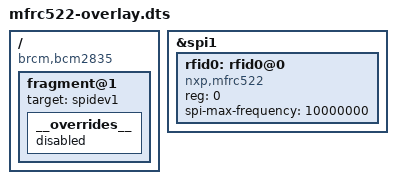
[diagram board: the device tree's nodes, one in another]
/dts-v1/;
/plugin/;


/ {
	compatible = "brcm,bcm2835";

	fragment@0 {
		target = <&spi1>;
		__overlay__ {
			/* needed to avoid dtc warning */
			#address-cells = <1>;
			#size-cells = <0>;
			status = "okay";

             		pinctrl-names = "default";
             		//pinctrl-0 = <&spi0_pins_s0>;

			rfid0: rfid0@0 {
				compatible = "nxp,mfrc522";
				reg = <0>;      /* CE0 */
				spi-max-frequency = <10000000>;
			};
		};
	};

	fragment@1 {
		target = <&spidev1>;
		__overrides__ {
			status = "disabled";
		};
	};  
};
